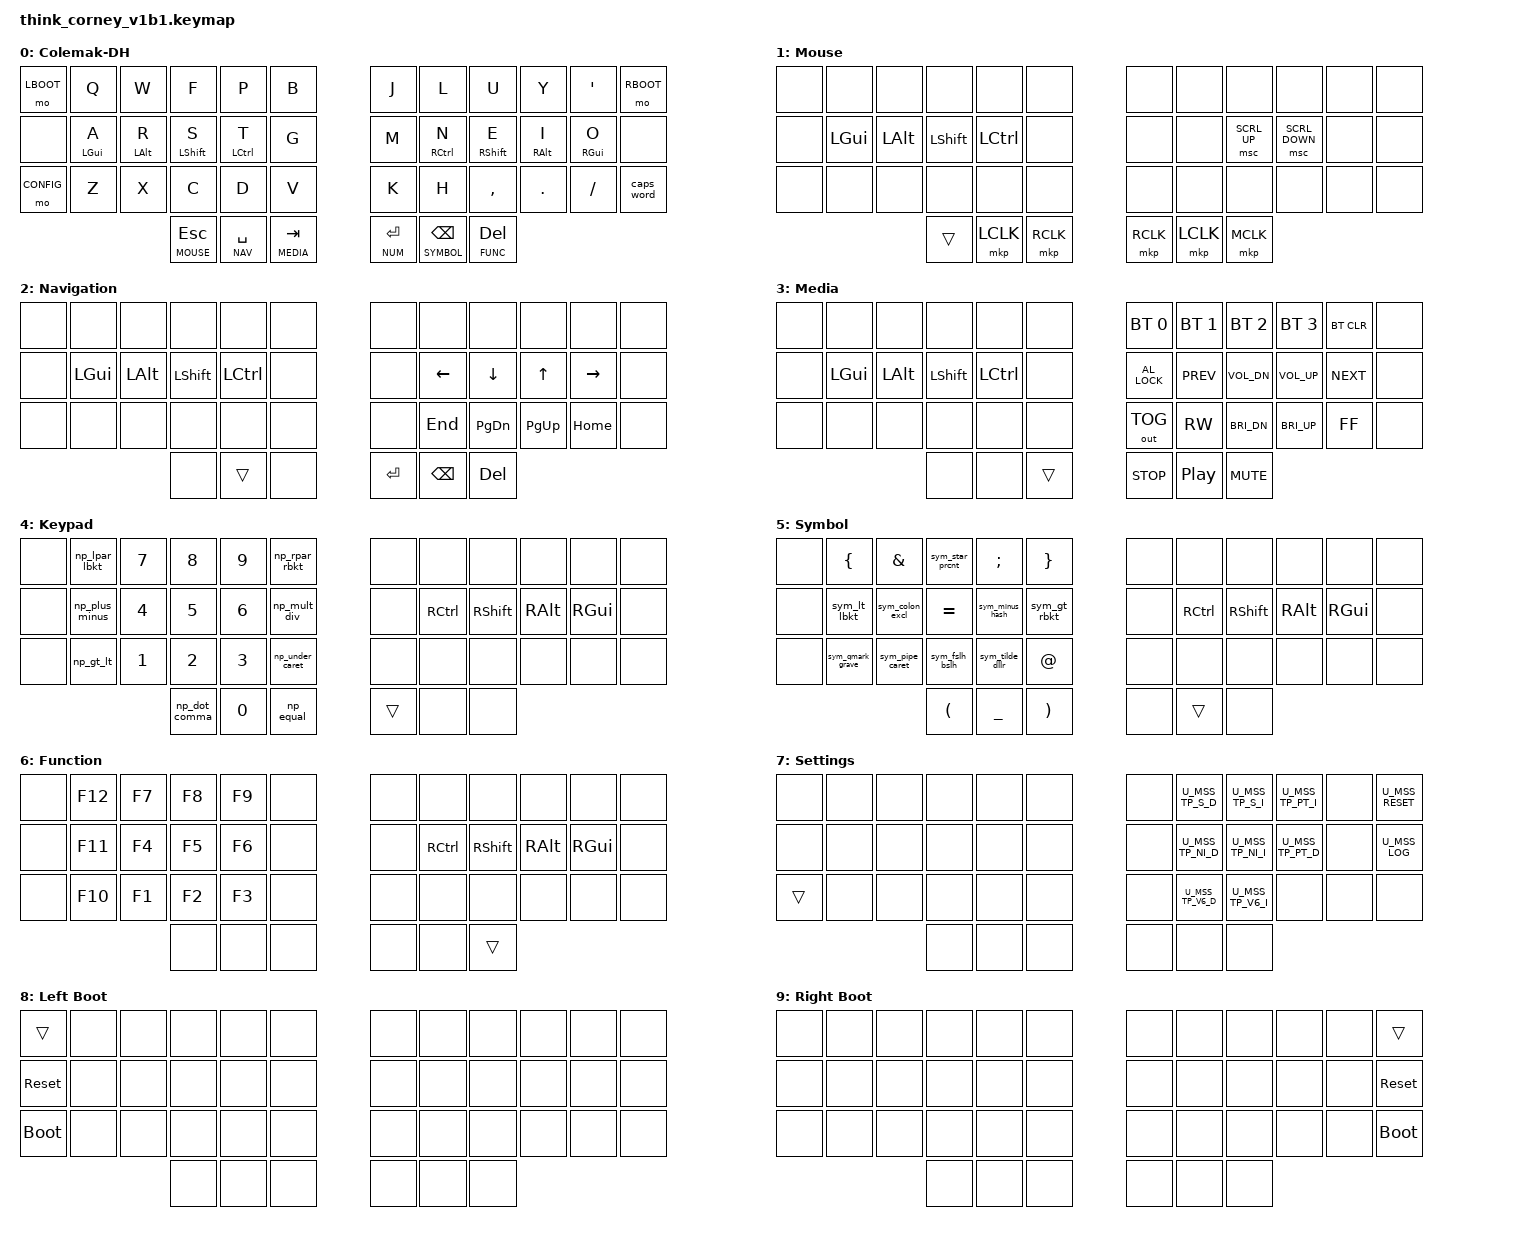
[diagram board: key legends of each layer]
#include <behaviors.dtsi>

#include <dt-bindings/zmk/keys.h>
#include <dt-bindings/zmk/bt.h>
#include <dt-bindings/zmk/outputs.h>
#include <dt-bindings/zmk/mouse.h>

#define ALPHA 0
#define MOUSE 1
#define NAV 2
#define MEDIA 3
#define NUM 4
#define SYMBOL 5
#define FUNC 6
#define CONFIG 7
#define LBOOT 8
#define RBOOT 9

#define HAS_MOUSE_KEYS
#define HAS_MOUSE_TP

#ifdef HAS_MOUSE_KEYS
  #include <dt-bindings/zmk/mouse.h>
  #include <behaviors/mouse_keys.dtsi>
#endif

#ifdef HAS_MOUSE_TP
  #include "include/mouse_tp.dtsi"
#endif

#include "include/behavior_mod_morph.dtsi"


/ {

  keymap {
    compatible = "zmk,keymap";

    Alpha_layer {
      display-name = "Colemak-DH";
      bindings = <
// ╭──────────────────┬──────────────────┬──────────────────┬──────────────────┬──────────────────┬──────────────────╮    ╭──────────────────┬──────────────────┬──────────────────┬──────────────────┬──────────────────┬──────────────────╮
     &mo LBOOT          &kp Q              &kp W              &kp F              &kp P              &kp B                   &kp J              &kp L              &kp U              &kp Y              &kp SQT            &mo RBOOT
// ├──────────────────┼──────────────────┼──────────────────┼──────────────────┼──────────────────┼──────────────────┤    ├──────────────────┼──────────────────┼──────────────────┼──────────────────┼──────────────────┼──────────────────┤
     &none              &mt LGUI A         &mt LALT R         &mt LSHFT S        &mt LCTRL T        &kp G                   &kp M              &mt RCTRL N        &mt RSHFT E        &mt RALT I         &mt RGUI O         &none
// ├──────────────────┼──────────────────┼──────────────────┼──────────────────┼──────────────────┼──────────────────┤    ├──────────────────┼──────────────────┼──────────────────┼──────────────────┼──────────────────┼──────────────────┤
     &mo CONFIG         &kp Z              &kp X              &kp C              &kp D              &kp V                   &kp K              &kp H              &kp COMMA          &kp PERIOD         &kp SLASH          &caps_word
// ╰──────────────────┴──────────────────┴──────────────────┴──────────────────┼──────────────────┼──────────────────┤    ├──────────────────┼──────────────────┼──────────────────┼──────────────────┴──────────────────┴──────────────────╯
                                                              &lt MOUSE ESC      &lt NAV SPACE      &lt MEDIA TAB           &lt NUM RET        &lt SYMBOL BSPC    &lt FUNC DEL
//                                                          ╰──────────────────┴──────────────────┴──────────────────╯    ╰──────────────────┴──────────────────┴──────────────────╯
      >;
    };

#ifdef HAS_MOUSE_KEYS
    Mouse_layer {
      display-name = "Mouse";
      bindings = <
// ╭──────────────────┬──────────────────┬──────────────────┬──────────────────┬──────────────────┬──────────────────╮    ╭──────────────────┬──────────────────┬──────────────────┬──────────────────┬──────────────────┬──────────────────╮
     &none              &none              &none              &none              &none              &none                   &none              &none              &none              &none              &none              &none
// ├──────────────────┼──────────────────┼──────────────────┼──────────────────┼──────────────────┼──────────────────┤    ├──────────────────┼──────────────────┼──────────────────┼──────────────────┼──────────────────┼──────────────────┤
     &none              &kp LGUI           &kp LALT           &kp LSHFT          &kp LCTRL          &none                   &none              &none              &msc SCRL_UP       &msc SCRL_DOWN     &none              &none
// ├──────────────────┼──────────────────┼──────────────────┼──────────────────┼──────────────────┼──────────────────┤    ├──────────────────┼──────────────────┼──────────────────┼──────────────────┼──────────────────┼──────────────────┤
     &none              &none              &none              &none              &none              &none                   &none              &none              &none              &none              &none              &none
// ╰──────────────────┴──────────────────┴──────────────────┴──────────────────┼──────────────────┼──────────────────┤    ├──────────────────┼──────────────────┼──────────────────┼──────────────────┴──────────────────┴──────────────────╯
                                                              &trans             &mkp LCLK          &mkp RCLK               &mkp RCLK          &mkp LCLK          &mkp MCLK
//                                                          ╰──────────────────┴──────────────────┴──────────────────╯    ╰──────────────────┴──────────────────┴──────────────────╯
      >;
    };
#else
    Mouse_layer {
      display-name = "Mouse";
      bindings = <
// ╭──────────────────┬──────────────────┬──────────────────┬──────────────────┬──────────────────┬──────────────────╮    ╭──────────────────┬──────────────────┬──────────────────┬──────────────────┬──────────────────┬──────────────────╮
     &none              &none              &none              &none              &none              &none                   &none              &none              &none              &none              &none              &none
// ├──────────────────┼──────────────────┼──────────────────┼──────────────────┼──────────────────┼──────────────────┤    ├──────────────────┼──────────────────┼──────────────────┼──────────────────┼──────────────────┼──────────────────┤
     &none              &kp LGUI           &kp LALT           &kp LSHFT          &kp LCTRL          &none                   &none              &none              &none              &none              &none              &none
// ├──────────────────┼──────────────────┼──────────────────┼──────────────────┼──────────────────┼──────────────────┤    ├──────────────────┼──────────────────┼──────────────────┼──────────────────┼──────────────────┼──────────────────┤
     &none              &none              &none              &none              &none              &none                   &none              &none              &none              &none              &none              &none
// ╰──────────────────┴──────────────────┴──────────────────┴──────────────────┼──────────────────┼──────────────────┤    ├──────────────────┼──────────────────┼──────────────────┼──────────────────┴──────────────────┴──────────────────╯
                                                              &trans             &mkp LCLK          &mkp RCLK               &mkp RCLK          &mkp LCLK          &mkp MCLK
//                                                          ╰──────────────────┴──────────────────┴──────────────────╯    ╰──────────────────┴──────────────────┴──────────────────╯
      >;
    };
#endif

      /*
       * For navigating tabs in browsers, one can use ~ALT + GUI + LEFT/RIGHT~
       */

    Nav_layer {
      display-name = "Navigation";
      bindings = <
// ╭──────────────────┬──────────────────┬──────────────────┬──────────────────┬──────────────────┬──────────────────╮    ╭──────────────────┬──────────────────┬──────────────────┬──────────────────┬──────────────────┬──────────────────╮
     &none              &none              &none              &none              &none              &none                   &none              &none              &none              &none              &none              &none
// ├──────────────────┼──────────────────┼──────────────────┼──────────────────┼──────────────────┼──────────────────┤    ├──────────────────┼──────────────────┼──────────────────┼──────────────────┼──────────────────┼──────────────────┤
     &none              &kp LGUI           &kp LALT           &kp LSHFT          &kp LCTRL          &none                   &none              &kp LEFT           &kp DOWN           &kp UP             &kp RIGHT          &none
// ├──────────────────┼──────────────────┼──────────────────┼──────────────────┼──────────────────┼──────────────────┤    ├──────────────────┼──────────────────┼──────────────────┼──────────────────┼──────────────────┼──────────────────┤
     &none              &none              &none              &none              &none              &none                   &none              &kp END            &kp PG_DN          &kp PG_UP          &kp HOME           &none
// ╰──────────────────┴──────────────────┴──────────────────┴──────────────────┼──────────────────┼──────────────────┤    ├──────────────────┼──────────────────┼──────────────────┼──────────────────┴──────────────────┴──────────────────╯
                                                              &none              &trans             &none                   &kp RET            &kp BSPC           &kp DEL
//                                                          ╰──────────────────┴──────────────────┴──────────────────╯    ╰──────────────────┴──────────────────┴──────────────────╯
      >;
    };

    Media_layer {
      display-name = "Media";
      bindings = <
// ╭──────────────────┬──────────────────┬──────────────────┬──────────────────┬──────────────────┬──────────────────╮    ╭──────────────────┬──────────────────┬──────────────────┬──────────────────┬──────────────────┬──────────────────╮
     &none              &none              &none              &none              &none              &none                   &bt BT_SEL 0       &bt BT_SEL 1       &bt BT_SEL 2       &bt BT_SEL 3       &bt BT_CLR         &none
// ├──────────────────┼──────────────────┼──────────────────┼──────────────────┼──────────────────┼──────────────────┤    ├──────────────────┼──────────────────┼──────────────────┼──────────────────┼──────────────────┼──────────────────┤
     &none              &kp LGUI           &kp LALT           &kp LSHFT          &kp LCTRL          &none                   &kp C_AL_LOCK      &kp C_PREV         &kp C_VOL_DN       &kp C_VOL_UP       &kp C_NEXT         &none
// ├──────────────────┼──────────────────┼──────────────────┼──────────────────┼──────────────────┼──────────────────┤    ├──────────────────┼──────────────────┼──────────────────┼──────────────────┼──────────────────┼──────────────────┤
     &none              &none              &none              &none              &none              &none                   &out OUT_TOG       &kp C_RW           &kp C_BRI_DN       &kp C_BRI_UP       &kp C_FF           &none
// ╰──────────────────┴──────────────────┴──────────────────┴──────────────────┼──────────────────┼──────────────────┤    ├──────────────────┼──────────────────┼──────────────────┼──────────────────┴──────────────────┴──────────────────╯
                                                              &none              &none              &trans                  &kp C_STOP         &kp C_PP           &kp C_MUTE
//                                                          ╰──────────────────┴──────────────────┴──────────────────╯    ╰──────────────────┴──────────────────┴──────────────────╯
      >;
    };

      /*
       * This layer is supposed to function similar to a numpad.
       * Mod morphs are used here to consolidate symbols that are
       * commonly used with numbers onto this one layer. The numbers
       * are not intended to be used with shift to produce any
       * symbols so that this layer maintains a clear purpose and
       * logic arrangement. Therefore, you will see some symbols
       * that could be achieved with S-<Number> will have a
       * dedicated mod morph instead.
       *
       * The dedicated keypad keys are not used here because they
       * are less common and cause undesired behavior in some
       * applications.
       */

    Num_layer {
      display-name = "Keypad";
      bindings = <
// ╭──────────────────┬──────────────────┬──────────────────┬──────────────────┬──────────────────┬──────────────────╮    ╭──────────────────┬──────────────────┬──────────────────┬──────────────────┬──────────────────┬──────────────────╮
     &none              &np_lpar_lbkt      &kp N7             &kp N8             &kp N9             &np_rpar_rbkt           &none              &none              &none              &none              &none              &none
// ├──────────────────┼──────────────────┼──────────────────┼──────────────────┼──────────────────┼──────────────────┤    ├──────────────────┼──────────────────┼──────────────────┼──────────────────┼──────────────────┼──────────────────┤
     &none              &np_plus_minus     &kp N4             &kp N5             &kp N6             &np_mult_div            &none              &kp RCTRL          &kp RSHFT          &kp RALT           &kp RGUI           &none
// ├──────────────────┼──────────────────┼──────────────────┼──────────────────┼──────────────────┼──────────────────┤    ├──────────────────┼──────────────────┼──────────────────┼──────────────────┼──────────────────┼──────────────────┤
     &none              &np_gt_lt          &kp N1             &kp N2             &kp N3             &np_under_caret         &none              &none              &none              &none              &none              &none
// ╰──────────────────┴──────────────────┴──────────────────┴──────────────────┼──────────────────┼──────────────────┤    ├──────────────────┼──────────────────┼──────────────────┼──────────────────┴──────────────────┴──────────────────╯
                                                              &np_dot_comma      &kp N0             &np_equal               &trans             &none              &none
//                                                          ╰──────────────────┴──────────────────┴──────────────────╯    ╰──────────────────┴──────────────────┴──────────────────╯
      >;
    };

      /*
       * This symbol layer has been designed mainly with the idea
       * of programming in mind. It tries to make common symbols
       * used while programming easy to type while also arranging
       * the keys in a way that make typing common bigrams easy
       * as well. I followed the idea of typing inwards for the
       * bigrams. I also preferred having two symbols on a
       * homerow key and using shift versus have the symbols on
       * two separate keys if one of them was not in the homerow.
       *
       *
       * It is centered around '=' since it is very
       * common across various languages and is a component in
       * many bigrams (and trigrams):
       *
       *  +=, -=, *=, /=, %=, &=, |=, ^=, !=, ==, <=, =>, :=
       *  >>=, <<=, >==, >==, !==
       *
       * Both the right and left angle brackets also see much use
       * so they are on the top layer as well.
       *
       * All the brackets and braces see lots of use in syntax
       * heavy languages. I would reasonably say that the
       * parentheses see the most universally use, so they are
       * assigned to the thumb keys. I decided to include the
       * braces ({, }) over the brackets ([, ]) as the primary
       * key (i.e. when not holding shift) because I think they
       * see more use than the brackets.
       *
       * I made the choice to include colon on the home row as
       * well since it sees decent use, specifically in Python
       * where many of the other symbols are not used, but also
       * in certain declarations like structs or json.
       *
       * A few other noteworthy details:
       * - The underscore is where space is on the alpha layer
       * to assist in typing snakecase
       * - You'll notice some 'symbols' are missing from this
       * layer. Things like single/double quote, period, and
       * comma. These are located on the alpha layer as they are
       * usually combined with letters even in the context of
       * programming.
       * There are some other bigrams I have tried to include
       * like -> and ~/
       *
       * Disclaimer: This is based on my reasoning and I have
       * not done any analysis to arrive at this layout.
       */

    Sym_layer {
      display-name = "Symbol";
      bindings = <
// ╭──────────────────┬──────────────────┬──────────────────┬──────────────────┬──────────────────┬──────────────────╮    ╭──────────────────┬──────────────────┬──────────────────┬──────────────────┬──────────────────┬──────────────────╮
     &none              &kp LBRC           &kp AMPS           &sym_star_prcnt    &kp SEMI           &kp RBRC                &none              &none              &none              &none              &none              &none
// ├──────────────────┼──────────────────┼──────────────────┼──────────────────┼──────────────────┼──────────────────┤    ├──────────────────┼──────────────────┼──────────────────┼──────────────────┼──────────────────┼──────────────────┤
     &none              &sym_lt_lbkt       &sym_colon_excl    &kp EQUAL          &sym_minus_hash    &sym_gt_rbkt            &none              &kp RCTRL          &kp RSHFT          &kp RALT           &kp RGUI           &none
// ├──────────────────┼──────────────────┼──────────────────┼──────────────────┼──────────────────┼──────────────────┤    ├──────────────────┼──────────────────┼──────────────────┼──────────────────┼──────────────────┼──────────────────┤
     &none              &sym_qmark_grave   &sym_pipe_caret    &sym_fslh_bslh     &sym_tilde_dllr    &kp AT                  &none              &none              &none              &none              &none              &none
// ╰──────────────────┴──────────────────┴──────────────────┴──────────────────┼──────────────────┼──────────────────┤    ├──────────────────┼──────────────────┼──────────────────┼──────────────────┴──────────────────┴──────────────────╯
                                                              &kp LPAR           &kp UNDER          &kp RPAR                &none              &trans             &none
//                                                          ╰──────────────────┴──────────────────┴──────────────────╯    ╰──────────────────┴──────────────────┴──────────────────╯
      >;
    };

    Func_layer {
      display-name = "Function";
      bindings = <
// ╭──────────────────┬──────────────────┬──────────────────┬──────────────────┬──────────────────┬──────────────────╮    ╭──────────────────┬──────────────────┬──────────────────┬──────────────────┬──────────────────┬──────────────────╮
     &none              &kp F12            &kp F7             &kp F8             &kp F9             &none                   &none              &none              &none              &none              &none              &none
// ├──────────────────┼──────────────────┼──────────────────┼──────────────────┼──────────────────┼──────────────────┤    ├──────────────────┼──────────────────┼──────────────────┼──────────────────┼──────────────────┼──────────────────┤
     &none              &kp F11            &kp F4             &kp F5             &kp F6             &none                   &none              &kp RCTRL          &kp RSHFT          &kp RALT           &kp RGUI           &none
// ├──────────────────┼──────────────────┼──────────────────┼──────────────────┼──────────────────┼──────────────────┤    ├──────────────────┼──────────────────┼──────────────────┼──────────────────┼──────────────────┼──────────────────┤
     &none              &kp F10            &kp F1             &kp F2             &kp F3             &none                   &none              &none              &none              &none              &none              &none
// ╰──────────────────┴──────────────────┴──────────────────┴──────────────────┼──────────────────┼──────────────────┤    ├──────────────────┼──────────────────┼──────────────────┼──────────────────┴──────────────────┴──────────────────╯
                                                              &none              &none              &none                   &none              &none              &trans
//                                                          ╰──────────────────┴──────────────────┴──────────────────╯    ╰──────────────────┴──────────────────┴──────────────────╯
      >;
    };

#ifdef HAS_MOUSE_TP
    Config_layer {
      display-name = "Settings";
      bindings = <
// ╭──────────────────┬──────────────────┬──────────────────┬──────────────────┬──────────────────┬──────────────────╮    ╭──────────────────┬──────────────────┬──────────────────┬──────────────────┬──────────────────┬──────────────────╮
     &none              &none              &none              &none              &none              &none                   &none              U_MSS_TP_S_D       U_MSS_TP_S_I       U_MSS_TP_PT_I      &none              U_MSS_RESET
// ├──────────────────┼──────────────────┼──────────────────┼──────────────────┼──────────────────┼──────────────────┤    ├──────────────────┼──────────────────┼──────────────────┼──────────────────┼──────────────────┼──────────────────┤
     &none              &none              &none              &none              &none              &none                   &none              U_MSS_TP_NI_D      U_MSS_TP_NI_I      U_MSS_TP_PT_D      &none              U_MSS_LOG
// ├──────────────────┼──────────────────┼──────────────────┼──────────────────┼──────────────────┼──────────────────┤    ├──────────────────┼──────────────────┼──────────────────┼──────────────────┼──────────────────┼──────────────────┤
     &trans             &none              &none              &none              &none              &none                   &none              U_MSS_TP_V6_D      U_MSS_TP_V6_I      &none              &none              &none
// ╰──────────────────┴──────────────────┴──────────────────┴──────────────────┼──────────────────┼──────────────────┤    ├──────────────────┼──────────────────┼──────────────────┼──────────────────┴──────────────────┴──────────────────╯
                                                              &none              &none              &none                   &none              &none              &none
//                                                          ╰──────────────────┴──────────────────┴──────────────────╯    ╰──────────────────┴──────────────────┴──────────────────╯
      >;
    };
#else
    Config_layer {
      display-name = "Settings";
      bindings = <
// ╭──────────────────┬──────────────────┬──────────────────┬──────────────────┬──────────────────┬──────────────────╮    ╭──────────────────┬──────────────────┬──────────────────┬──────────────────┬──────────────────┬──────────────────╮
     &none              &none              &none              &none              &none              &none                   &none              &none              &none              &none              &none              &none
// ├──────────────────┼──────────────────┼──────────────────┼──────────────────┼──────────────────┼──────────────────┤    ├──────────────────┼──────────────────┼──────────────────┼──────────────────┼──────────────────┼──────────────────┤
     &none              &none              &none              &none              &none              &none                   &none              &none              &none              &none              &none              &none
// ├──────────────────┼──────────────────┼──────────────────┼──────────────────┼──────────────────┼──────────────────┤    ├──────────────────┼──────────────────┼──────────────────┼──────────────────┼──────────────────┼──────────────────┤
     &trans             &none              &none              &none              &none              &none                   &none              &none              &none              &none              &none              &none
// ╰──────────────────┴──────────────────┴──────────────────┴──────────────────┼──────────────────┼──────────────────┤    ├──────────────────┼──────────────────┼──────────────────┼──────────────────┴──────────────────┴──────────────────╯
                                                              &none              &none              &none                   &none              &none              &none
//                                                          ╰──────────────────┴──────────────────┴──────────────────╯    ╰──────────────────┴──────────────────┴──────────────────╯
      >;
    };
#endif

    Left_Boot_layer {
      display-name = "Left Boot";
      bindings = <
// ╭──────────────────┬──────────────────┬──────────────────┬──────────────────┬──────────────────┬──────────────────╮    ╭──────────────────┬──────────────────┬──────────────────┬──────────────────┬──────────────────┬──────────────────╮
     &trans             &none              &none              &none              &none              &none                   &none              &none              &none              &none              &none              &none
// ├──────────────────┼──────────────────┼──────────────────┼──────────────────┼──────────────────┼──────────────────┤    ├──────────────────┼──────────────────┼──────────────────┼──────────────────┼──────────────────┼──────────────────┤
     &sys_reset         &none              &none              &none              &none              &none                   &none              &none              &none              &none              &none              &none
// ├──────────────────┼──────────────────┼──────────────────┼──────────────────┼──────────────────┼──────────────────┤    ├──────────────────┼──────────────────┼──────────────────┼──────────────────┼──────────────────┼──────────────────┤
     &bootloader        &none              &none              &none              &none              &none                   &none              &none              &none              &none              &none              &none
// ╰──────────────────┴──────────────────┴──────────────────┴──────────────────┼──────────────────┼──────────────────┤    ├──────────────────┼──────────────────┼──────────────────┼──────────────────┴──────────────────┴──────────────────╯
                                                              &none              &none              &none                   &none              &none              &none
//                                                          ╰──────────────────┴──────────────────┴──────────────────╯    ╰──────────────────┴──────────────────┴──────────────────╯
      >;
    };

    Right_Boot_layer {
      display-name = "Right Boot";
      bindings = <
// ╭──────────────────┬──────────────────┬──────────────────┬──────────────────┬──────────────────┬──────────────────╮    ╭──────────────────┬──────────────────┬──────────────────┬──────────────────┬──────────────────┬──────────────────╮
     &none              &none              &none              &none              &none              &none                   &none              &none              &none              &none              &none              &trans
// ├──────────────────┼──────────────────┼──────────────────┼──────────────────┼──────────────────┼──────────────────┤    ├──────────────────┼──────────────────┼──────────────────┼──────────────────┼──────────────────┼──────────────────┤
     &none              &none              &none              &none              &none              &none                   &none              &none              &none              &none              &none              &sys_reset
// ├──────────────────┼──────────────────┼──────────────────┼──────────────────┼──────────────────┼──────────────────┤    ├──────────────────┼──────────────────┼──────────────────┼──────────────────┼──────────────────┼──────────────────┤
     &none              &none              &none              &none              &none              &none                   &none              &none              &none              &none              &none              &bootloader
// ╰──────────────────┴──────────────────┴──────────────────┴──────────────────┼──────────────────┼──────────────────┤    ├──────────────────┼──────────────────┼──────────────────┼──────────────────┴──────────────────┴──────────────────╯
                                                              &none              &none              &none                   &none              &none              &none
//                                                          ╰──────────────────┴──────────────────┴──────────────────╯    ╰──────────────────┴──────────────────┴──────────────────╯
      >;
    };

  };
};
